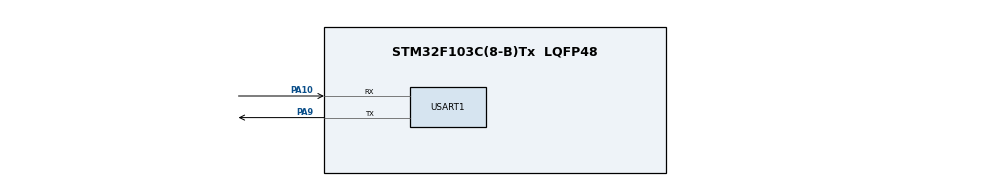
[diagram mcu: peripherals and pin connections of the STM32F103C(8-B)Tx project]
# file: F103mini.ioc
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Mcu.Family=STM32F1
Mcu.Name=STM32F103C(8-B)Tx
Mcu.Package=LQFP48
NVIC.PriorityGroup=NVIC_PRIORITYGROUP_4
PA10.Mode=Asynchronous
PA10.Signal=USART1_RX
PA13.Mode=Serial_Wire
PA13.Signal=SYS_JTMS-SWDIO
PA14.Mode=Serial_Wire
PA14.Signal=SYS_JTCK-SWCLK
PA9.Mode=Asynchronous
PA9.Signal=USART1_TX
PC14-OSC32_IN.Mode=LSE-External-Oscillator
PC14-OSC32_IN.Signal=RCC_OSC32_IN
PC15-OSC32_OUT.Mode=LSE-External-Oscillator
PC15-OSC32_OUT.Signal=RCC_OSC32_OUT
PD0-OSC_IN.Mode=HSE-External-Oscillator
PD0-OSC_IN.Signal=RCC_OSC_IN
PD1-OSC_OUT.Mode=HSE-External-Oscillator
PD1-OSC_OUT.Signal=RCC_OSC_OUT
ProjectManager.HeapSize=0x200
ProjectManager.StackSize=0x400
ProjectManager.TargetToolchain=SW4STM32
RCC.APB1Freq_Value=8000000
RCC.APB2Freq_Value=8000000
RCC.ClockTypeHCLK=RCC_CLOCKTYPE_HCLK
RCC.ClockTypePCLK1=RCC_CLOCKTYPE_PCLK1
RCC.ClockTypePCLK2=RCC_CLOCKTYPE_PCLK2
RCC.EnableHSE=true
RCC.EnableHSERTCDevisor=true
RCC.EnableLSE=true
RCC.EnableLSERTC=true
RCC.EnableMCOMultDivisor=false
RCC.EnbaleCSS=true
RCC.HSEState=RCC_HSE_ON
RCC.HSIState=RCC_HSI_ON
RCC.IWDGEnable=false
RCC.LSEState=RCC_LSE_ON
RCC.LSIState=RCC_LSI_OFF
RCC.MCOEnable=false
RCC.OscillatorTypeHSE=RCC_OSCILLATORTYPE_HSE
RCC.OscillatorTypeHSI=RCC_OSCILLATORTYPE_HSI
RCC.OscillatorTypeLSE=RCC_OSCILLATORTYPE_LSE
RCC.PLLSource=RCC_PLLSOURCE_HSE
RCC.PLLSourceVirtual=RCC_PLLSOURCE_HSE
RCC.PLLState=RCC_PLL_OFF
RCC.RCC_PERIPHCLK_RTCVar=RCC_PERIPHCLK_RTC
RCC.RTCClockSelection=RCC_RTCCLKSOURCE_LSE
RCC.RTCEnable=true
RCC.SYSCLKSource=RCC_SYSCLKSOURCE_HSE
RCC.USBFreq_Value=16000000
USART1.HwFlowCtl-Asynchronous=UART_HWCONTROL_NONE
USART1.VirtualMode=VM_ASYNC
VP_RTC_VS_RTC_Activate.Mode=RTC_Enabled
board=F103mini

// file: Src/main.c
#include <uart1.h>
#include "main.h"
#include "stm32f1xx_hal.h"
#include "FreeRTOS.h"
#include "task.h"
#include "queue.h"

#include "rtc.h"
#include "rcc.h"
#include "gpio.h"

#define main_TASK_PRIORITY				( tskIDLE_PRIORITY + 1 )
/* The number of nano seconds between each processor clock. */
#define mainNS_PER_CLOCK ( ( unsigned long ) ( ( 1.0 / ( double ) configCPU_CLOCK_HZ ) * 1000000000.0 ) )

void vTaskLed1(void *pvParameters);

int main(void)
{
  HAL_Init();
  SystemClock_Config();
  /* Initialize all configured peripherals */
  MX_GPIO_Init();
  MX_RTC_Init();
  MX_USART1_UART_Init();

  /* USER CODE BEGIN 2 */
  xTaskCreate( vTaskLed1, "LED1", configMINIMAL_STACK_SIZE, NULL, main_TASK_PRIORITY, ( TaskHandle_t * ) NULL );
  vTaskStartScheduler();
  /* USER CODE END 2 */

  while (1)
  {
  }
  return 0;
}

/* USER CODE BEGIN 4 */
void vTaskLed1(void *pvParameters)
{
	for(;;)
	{
	vTaskDelay(1000 / portTICK_PERIOD_MS);
	}
}
/* USER CODE END 4 */

void Error_Handler(void)
{
  while(1)
  {
  }
}
